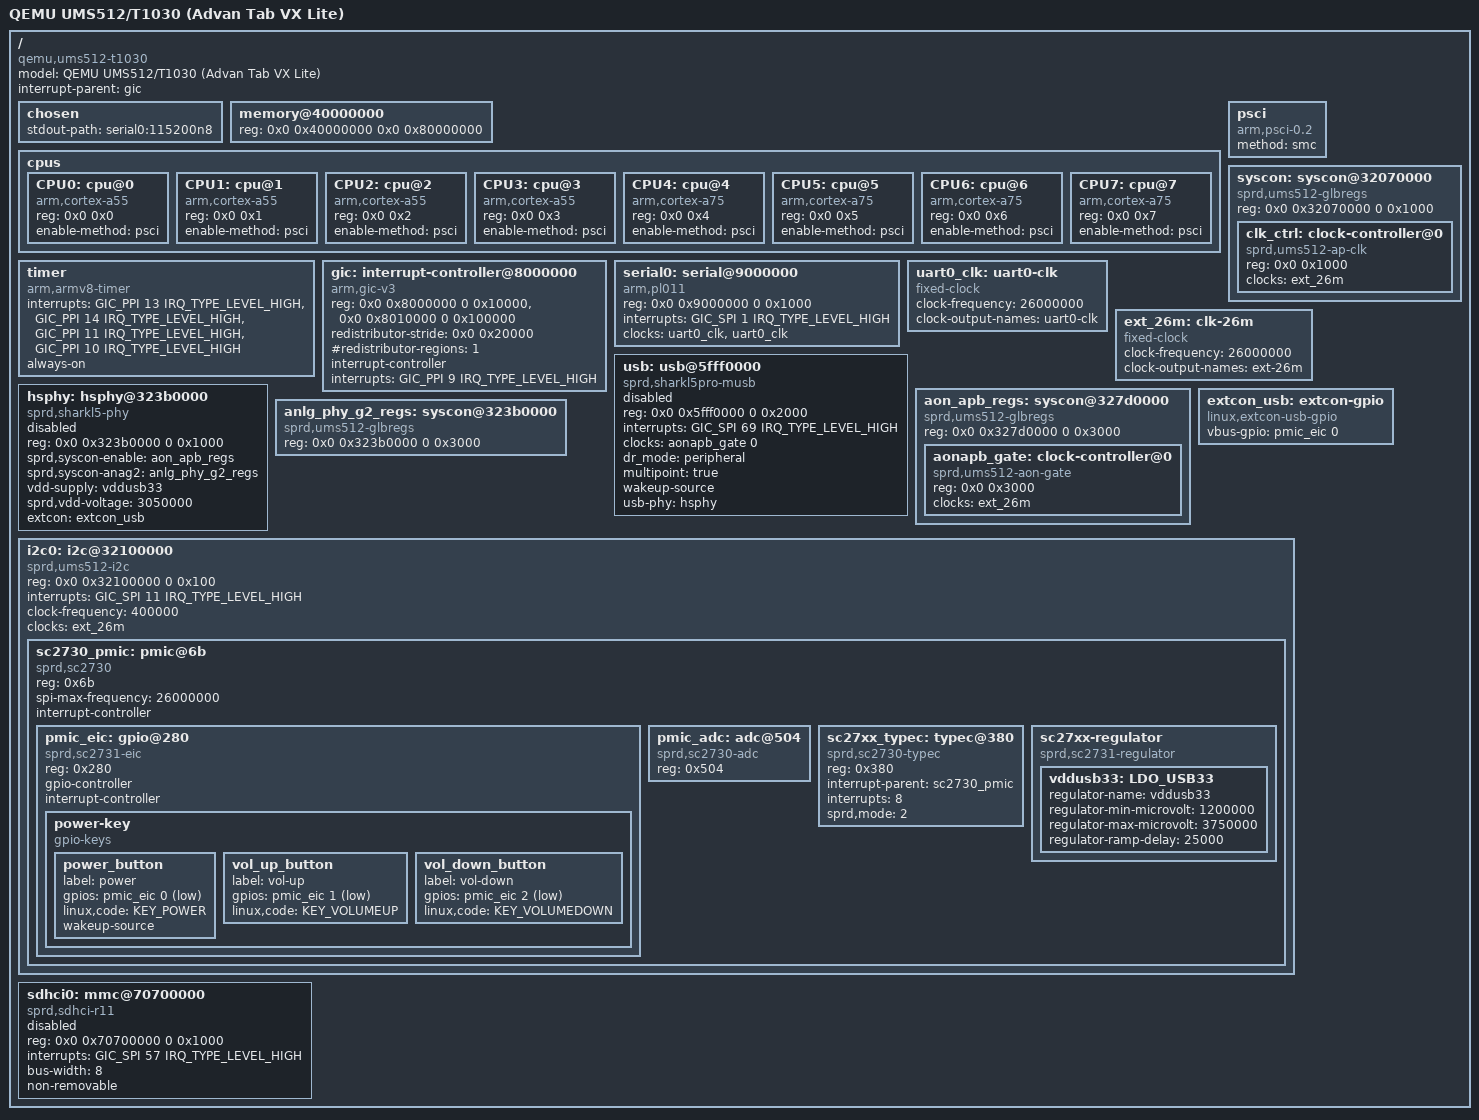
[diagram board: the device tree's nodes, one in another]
// SPDX-License-Identifier: (GPL-2.0 OR MIT)
/*
 * QEMU virt machine dengan perangkat UMS512/T1030 (Advan Tab VX Lite)
 *
 * Dibangun di atas peta memori QEMU -M virt yang sebenarnya:
 *   - RAM 2GB @ 0x40000000        (-m 2G)
 *   - GICv3 GICD @ 0x08000000, GICR @ 0x08010000 (stride 0x20000)
 *   - PL011 @ 0x09000000 (SPI 1). Driver AMBA PL011 sengaja tidak ada
 *     di tree V17 (lihat docs/CI-KNOWN-DROPPED.txt), jadi console boot
 *     memakai virtio-console: -device virtio-serial-pci
 *     -device virtconsole + console=hvc0.
 *   - MPIDR CPU linear 0..7 sesuai `-smp 8` QEMU virt. Register CPU lama
 *     0x100,0x200,... (Aff1) tidak pernah match topologi QEMU dan CPU
 *     sekunder tidak akan hidup.
 *
 * Node stub UMS512 dipertahankan untuk pengujian bertahap. Dua node yang
 * MMIO-nya jatuh DI DALAM RAM QEMU (musb @ 0x5fff0000, sdhci @ 0x70700000)
 * dipasang status="disabled": QEMU tidak memetakan perangkat itu, jadi
 * tulisan "register" driver akan jatuh ke memori tamu dan merusaknya.
 * File ini juga dirender LF (versi lama CRLF + terpotong di tengah node
 * sdhci sehingga tidak pernah bisa dikompilasi).
 */

/dts-v1/;

#include <dt-bindings/interrupt-controller/arm-gic.h>
#include <dt-bindings/interrupt-controller/irq.h>
#include <dt-bindings/gpio/gpio.h>
#include <dt-bindings/input/input.h>

/ {
	compatible = "qemu,ums512-t1030", "qemu,virt";
	#address-cells = <2>;
	#size-cells = <2>;

	model = "QEMU UMS512/T1030 (Advan Tab VX Lite)";
	interrupt-parent = <&gic>;

	chosen {
		stdout-path = "serial0:115200n8";
	};

	memory@40000000 {
		device_type = "memory";
		reg = <0x0 0x40000000 0x0 0x80000000>; /* 2GB @ 0x40000000 */
	};

	/* 8 cores: 4x Cortex-A55 + 4x Cortex-A75 (label disimpan) */
	cpus {
		#address-cells = <2>;
		#size-cells = <0>;

		CPU0: cpu@0 {
			device_type = "cpu";
			compatible = "arm,cortex-a55";
			reg = <0x0 0x0>;
			enable-method = "psci";
		};
		CPU1: cpu@1 {
			device_type = "cpu";
			compatible = "arm,cortex-a55";
			reg = <0x0 0x1>;
			enable-method = "psci";
		};
		CPU2: cpu@2 {
			device_type = "cpu";
			compatible = "arm,cortex-a55";
			reg = <0x0 0x2>;
			enable-method = "psci";
		};
		CPU3: cpu@3 {
			device_type = "cpu";
			compatible = "arm,cortex-a55";
			reg = <0x0 0x3>;
			enable-method = "psci";
		};
		CPU4: cpu@4 {
			device_type = "cpu";
			compatible = "arm,cortex-a75";
			reg = <0x0 0x4>;
			enable-method = "psci";
		};
		CPU5: cpu@5 {
			device_type = "cpu";
			compatible = "arm,cortex-a75";
			reg = <0x0 0x5>;
			enable-method = "psci";
		};
		CPU6: cpu@6 {
			device_type = "cpu";
			compatible = "arm,cortex-a75";
			reg = <0x0 0x6>;
			enable-method = "psci";
		};
		CPU7: cpu@7 {
			device_type = "cpu";
			compatible = "arm,cortex-a75";
			reg = <0x0 0x7>;
			enable-method = "psci";
		};
	};

	/* PSCI for CPU power management */
	psci {
		compatible = "arm,psci-0.2";
		method = "smc";
	};

	/* Generic timer */
	timer {
		compatible = "arm,armv8-timer";
		interrupts = <GIC_PPI 13 IRQ_TYPE_LEVEL_HIGH>,
			     <GIC_PPI 14 IRQ_TYPE_LEVEL_HIGH>,
			     <GIC_PPI 11 IRQ_TYPE_LEVEL_HIGH>,
			     <GIC_PPI 10 IRQ_TYPE_LEVEL_HIGH>;
		always-on;
	};

	/* GICv3 persis peta QEMU virt: GICD @ 0x08000000, GICR @ 0x08010000 */
	gic: interrupt-controller@8000000 {
		compatible = "arm,gic-v3";
		reg = <0x0 0x8000000 0 0x10000>,   /* GICD */
		      <0x0 0x8010000 0 0x100000>;  /* GICR: 8 redist x 0x20000 */
		#interrupt-cells = <3>;
		#address-cells = <2>;
		#size-cells = <2>;
		ranges;
		redistributor-stride = <0x0 0x20000>;
		#redistributor-regions = <1>;
		interrupt-controller;
		interrupts = <GIC_PPI 9 IRQ_TYPE_LEVEL_HIGH>;
	};

	/* System control / global registers for clock gating */
	syscon: syscon@32070000 {
		compatible = "sprd,ums512-glbregs", "syscon", "simple-mfd";
		reg = <0x0 0x32070000 0 0x1000>;
		#address-cells = <1>;
		#size-cells = <1>;
		ranges = <0 0 0x32070000 0x1000>;

		/* Clock controller stub for QEMU */
		clk_ctrl: clock-controller@0 {
			compatible = "sprd,ums512-ap-clk";
			reg = <0x0 0x1000>;
			clocks = <&ext_26m>;
			clock-names = "ext-26m";
			#clock-cells = <1>;
		};
	};

	/* PL011 UART di alamat asli QEMU virt (0x09000000, SPI 1) */
	serial0: serial@9000000 {
		compatible = "arm,pl011", "arm,primecell";
		reg = <0x0 0x9000000 0 0x1000>;
		interrupts = <GIC_SPI 1 IRQ_TYPE_LEVEL_HIGH>;
		clocks = <&uart0_clk>, <&uart0_clk>;
		clock-names = "uartclk", "apb_pclk";
		status = "okay";
	};

	/* Fixed 26MHz clock for UART and other peripherals */
	uart0_clk: uart0-clk {
		compatible = "fixed-clock";
		#clock-cells = <0>;
		clock-frequency = <26000000>;
		clock-output-names = "uart0-clk";
	};

	ext_26m: clk-26m {
		compatible = "fixed-clock";
		#clock-cells = <0>;
		clock-frequency = <26000000>;
		clock-output-names = "ext-26m";
	};

	/*
	 * MUSB USB OTG @ 0x5fff0000 — ADA DI DALAM RAM QEMU
	 * (0x40000000..0xbfffffff). QEMU tidak punya blok MUSB, jadi tulisan
	 * register driver akan mengubah memori tamu. Disabled.
	 */
	usb: usb@5fff0000 {
		compatible = "sprd,sharkl5pro-musb", "sprd,sharkl3-musb";
		reg = <0x0 0x5fff0000 0 0x2000>;
		interrupts = <GIC_SPI 69 IRQ_TYPE_LEVEL_HIGH>;
		interrupt-names = "mc";
		clocks = <&aonapb_gate 0>;
		clock-names = "core_clk";
		dr_mode = "peripheral";
		multipoint = "true";
		wakeup-source;
		status = "disabled";

		usb-phy = <&hsphy>;
		phy-names = "usb";
	};

	/* USB PHY @ 0x323b0000 — konsumen (musb) disabled, ikut disabled */
	hsphy: hsphy@323b0000 {
		compatible = "sprd,sharkl5-phy", "sprd,sharkl5pro-phy";
		reg = <0x0 0x323b0000 0 0x1000>;
		sprd,syscon-enable = <&aon_apb_regs>;
		sprd,syscon-anag2 = <&anlg_phy_g2_regs>;
		vdd-supply = <&vddusb33>;
		sprd,vdd-voltage = <3050000>;
		extcon = <&extcon_usb>;
		#phy-cells = <0>;
		status = "disabled";
	};

	/* AON APB registers for USB PHY enable */
	aon_apb_regs: syscon@327d0000 {
		compatible = "sprd,ums512-glbregs", "syscon", "simple-mfd";
		reg = <0x0 0x327d0000 0 0x3000>;
		#address-cells = <1>;
		#size-cells = <1>;
		ranges = <0 0 0x327d0000 0x3000>;

		aonapb_gate: clock-controller@0 {
			compatible = "sprd,ums512-aon-gate";
			reg = <0x0 0x3000>;
			clocks = <&ext_26m>;
			clock-names = "ext-26m";
			#clock-cells = <1>;
		};
	};

	/* Analog PHY G2 registers for USB PHY */
	anlg_phy_g2_regs: syscon@323b0000 {
		compatible = "sprd,ums512-glbregs", "syscon", "simple-mfd";
		reg = <0x0 0x323b0000 0 0x3000>;
		#address-cells = <1>;
		#size-cells = <1>;
		ranges = <0 0 0x323b0000 0x3000>;
	};

	/* EXTCON USB GPIO for VBUS detection */
	extcon_usb: extcon-gpio {
		compatible = "linux,extcon-usb-gpio";
		vbus-gpio = <&pmic_eic 0 GPIO_ACTIVE_HIGH>;
		status = "okay";
	};

	/* SC2730 PMIC at 0x32100000 (I2C 0x6B) - stubbed for QEMU */
	i2c0: i2c@32100000 {
		compatible = "sprd,ums512-i2c", "sprd,sc9860-i2c";
		reg = <0x0 0x32100000 0 0x100>;
		interrupts = <GIC_SPI 11 IRQ_TYPE_LEVEL_HIGH>;
		clock-frequency = <400000>;
		clocks = <&ext_26m>;
		#address-cells = <1>;
		#size-cells = <0>;
		status = "okay";

		/* SC2730 PMIC on I2C bus at address 0x6B */
		sc2730_pmic: pmic@6b {
			compatible = "sprd,sc2730";
			reg = <0x6b>;
			spi-max-frequency = <26000000>;
			interrupt-controller;
			#interrupt-cells = <1>;
			#address-cells = <1>;
			#size-cells = <0>;
			status = "okay";

			/* PMIC EIC (GPIO) for 3-button (power, vol+, vol-) */
			pmic_eic: gpio@280 {
				compatible = "sprd,sc2731-eic", "sprd,sc2730-eic";
				reg = <0x280>;
				gpio-controller;
				#gpio-cells = <2>;
				interrupt-controller;
				#interrupt-cells = <2>;
				status = "okay";

				/* 3-button keys: power, vol+, vol- */
				power-key {
					compatible = "gpio-keys";
					#address-cells = <1>;
					#size-cells = <0>;
					status = "okay";

					power_button {
						label = "power";
						gpios = <&pmic_eic 0 GPIO_ACTIVE_LOW>;
						linux,code = <KEY_POWER>;
						wakeup-source;
					};
					vol_up_button {
						label = "vol-up";
						gpios = <&pmic_eic 1 GPIO_ACTIVE_LOW>;
						linux,code = <KEY_VOLUMEUP>;
					};
					vol_down_button {
						label = "vol-down";
						gpios = <&pmic_eic 2 GPIO_ACTIVE_LOW>;
						linux,code = <KEY_VOLUMEDOWN>;
					};
				};
			};

			/* PMIC ADC for thermal */
			pmic_adc: adc@504 {
				compatible = "sprd,sc2730-adc";
				reg = <0x504>;
				#io-channel-cells = <1>;
				status = "okay";
			};

			/* Type-C/extcon */
			sc27xx_typec: typec@380 {
				compatible = "sprd,sc2730-typec", "sprd,sc27xx-typec";
				reg = <0x380>;
				interrupt-parent = <&sc2730_pmic>;
				interrupts = <8>;
				sprd,mode = <2>;
				status = "okay";
			};

			/* Regulators */
			sc27xx-regulator {
				compatible = "sprd,sc2731-regulator", "sprd,sc2730-regulator";
				status = "okay";

				vddusb33: LDO_USB33 {
					regulator-name = "vddusb33";
					regulator-min-microvolt = <1200000>;
					regulator-max-microvolt = <3750000>;
					regulator-ramp-delay = <25000>;
				};
			};
		};
	};

	/*
	 * eMMC/SD stub @ 0x70700000 — JUGA di dalam RAM QEMU dan QEMU tidak
	 * mempunya blok SDHCI Sprd. Disabled (lihat catatan di kepala file).
	 * Uji eMMC CMDQ tetap butuh hardware asli.
	 */
	sdhci0: mmc@70700000 {
		compatible = "sprd,sdhci-r11", "generic-sdhci";
		reg = <0x0 0x70700000 0 0x1000>;
		interrupts = <GIC_SPI 57 IRQ_TYPE_LEVEL_HIGH>;
		bus-width = <8>;
		non-removable;
		status = "disabled";
	};
};
